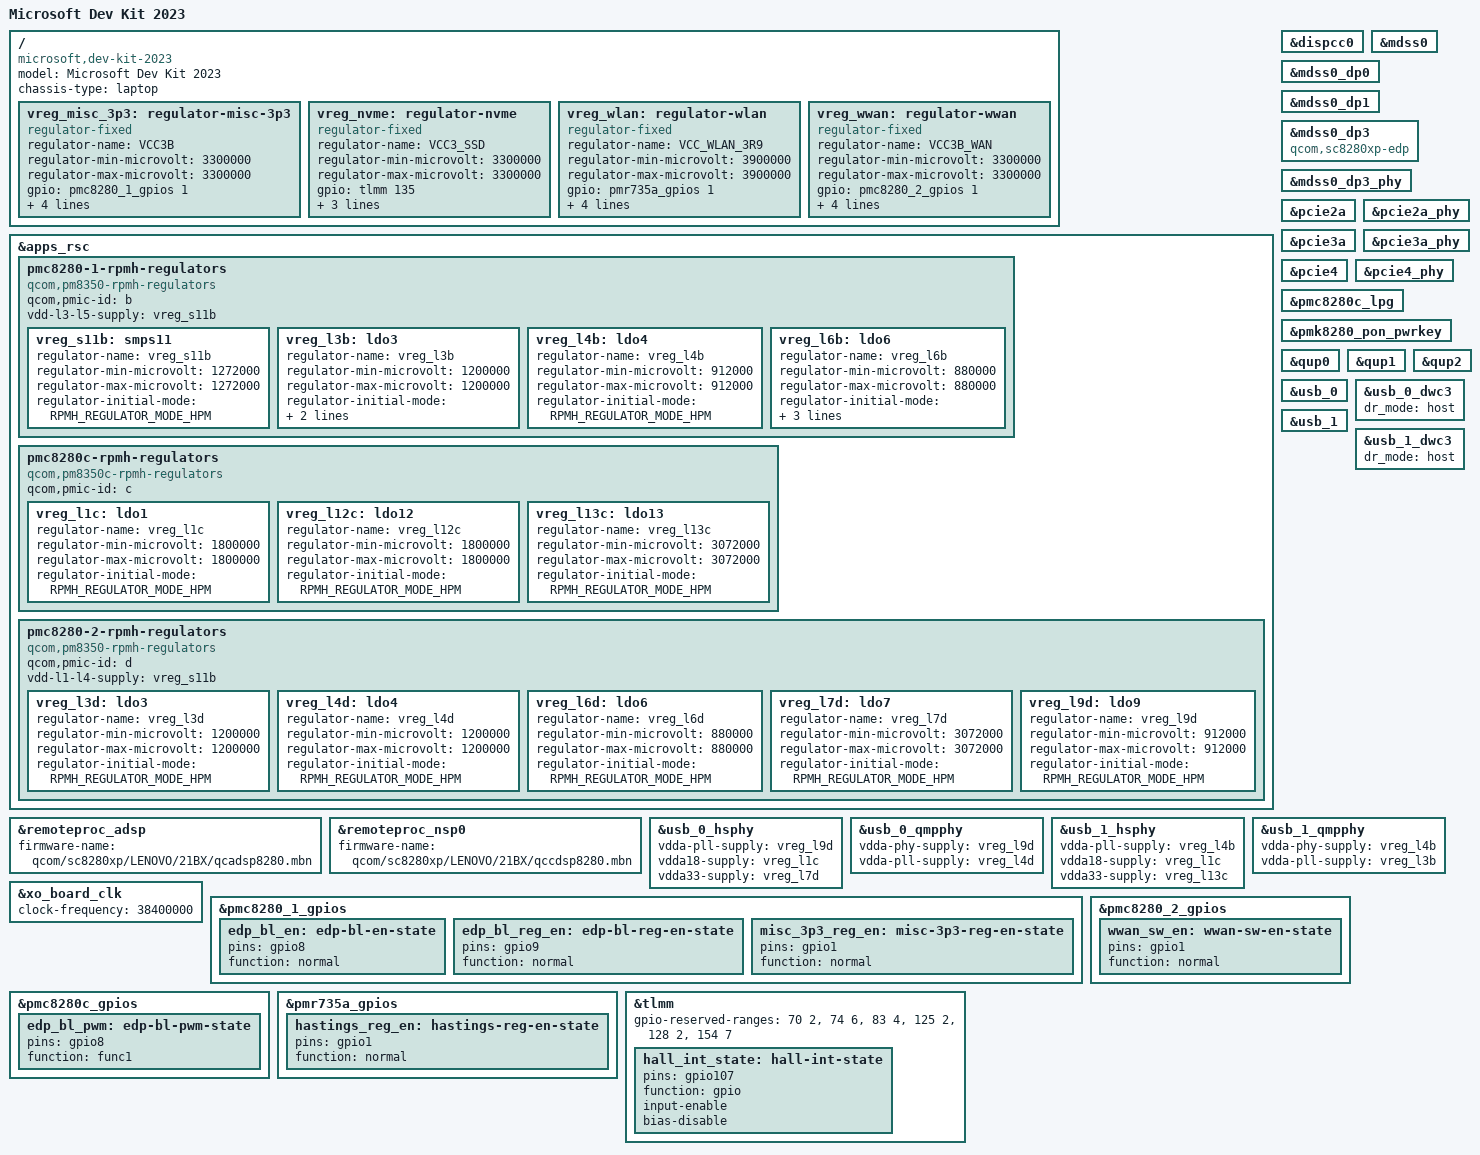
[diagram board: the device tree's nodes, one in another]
// SPDX-License-Identifier: BSD-3-Clause
/*
 * Copyright (c) 2021, The Linux Foundation. All rights reserved.
 * Copyright (c) 2022, Linaro Limited
 */

/dts-v1/;

#include <dt-bindings/gpio/gpio.h>
#include <dt-bindings/input/gpio-keys.h>
#include <dt-bindings/input/input.h>
#include <dt-bindings/regulator/qcom,rpmh-regulator.h>

#include "sc8280xp.dtsi"
#include "sc8280xp-pmics.dtsi"

/ {
	model = "Microsoft Dev Kit 2023";
	compatible = "microsoft,dev-kit-2023", "qcom,sc8280xp";
	chassis-type = "laptop";

	vreg_misc_3p3: regulator-misc-3p3 {
		compatible = "regulator-fixed";

		regulator-name = "VCC3B";
		regulator-min-microvolt = <3300000>;
		regulator-max-microvolt = <3300000>;

		gpio = <&pmc8280_1_gpios 1 GPIO_ACTIVE_HIGH>;
		enable-active-high;

		pinctrl-names = "default";
		pinctrl-0 = <&misc_3p3_reg_en>;

		regulator-boot-on;
		regulator-always-on;
	};

	vreg_nvme: regulator-nvme {
		compatible = "regulator-fixed";

		regulator-name = "VCC3_SSD";
		regulator-min-microvolt = <3300000>;
		regulator-max-microvolt = <3300000>;

		gpio = <&tlmm 135 GPIO_ACTIVE_HIGH>;
		enable-active-high;

		regulator-boot-on;
		regulator-always-on;
	};

	vreg_wlan: regulator-wlan {
		compatible = "regulator-fixed";

		regulator-name = "VCC_WLAN_3R9";
		regulator-min-microvolt = <3900000>;
		regulator-max-microvolt = <3900000>;

		gpio = <&pmr735a_gpios 1 GPIO_ACTIVE_HIGH>;
		enable-active-high;

		pinctrl-names = "default";
		pinctrl-0 = <&hastings_reg_en>;

		regulator-boot-on;
		regulator-always-on;
	};

	vreg_wwan: regulator-wwan {
		compatible = "regulator-fixed";

		regulator-name = "VCC3B_WAN";
		regulator-min-microvolt = <3300000>;
		regulator-max-microvolt = <3300000>;

		gpio = <&pmc8280_2_gpios 1 GPIO_ACTIVE_HIGH>;
		enable-active-high;

		pinctrl-names = "default";
		pinctrl-0 = <&wwan_sw_en>;

		regulator-boot-on;
		regulator-always-on;
	};
};

&apps_rsc {
	pmc8280-1-rpmh-regulators {
		compatible = "qcom,pm8350-rpmh-regulators";
		qcom,pmic-id = "b";

		vdd-l3-l5-supply = <&vreg_s11b>;

		vreg_s11b: smps11 {
			regulator-name = "vreg_s11b";
			regulator-min-microvolt = <1272000>;
			regulator-max-microvolt = <1272000>;
			regulator-initial-mode = <RPMH_REGULATOR_MODE_HPM>;
		};

		vreg_l3b: ldo3 {
			regulator-name = "vreg_l3b";
			regulator-min-microvolt = <1200000>;
			regulator-max-microvolt = <1200000>;
			regulator-initial-mode = <RPMH_REGULATOR_MODE_HPM>;
			regulator-boot-on;
		};

		vreg_l4b: ldo4 {
			regulator-name = "vreg_l4b";
			regulator-min-microvolt = <912000>;
			regulator-max-microvolt = <912000>;
			regulator-initial-mode = <RPMH_REGULATOR_MODE_HPM>;
		};

		vreg_l6b: ldo6 {
			regulator-name = "vreg_l6b";
			regulator-min-microvolt = <880000>;
			regulator-max-microvolt = <880000>;
			regulator-initial-mode = <RPMH_REGULATOR_MODE_HPM>;
			regulator-boot-on;
			regulator-always-on;	// FIXME: VDD_A_EDP_0_0P9
		};
	};

	pmc8280c-rpmh-regulators {
		compatible = "qcom,pm8350c-rpmh-regulators";
		qcom,pmic-id = "c";

		vreg_l1c: ldo1 {
			regulator-name = "vreg_l1c";
			regulator-min-microvolt = <1800000>;
			regulator-max-microvolt = <1800000>;
			regulator-initial-mode = <RPMH_REGULATOR_MODE_HPM>;
		};

		vreg_l12c: ldo12 {
			regulator-name = "vreg_l12c";
			regulator-min-microvolt = <1800000>;
			regulator-max-microvolt = <1800000>;
			regulator-initial-mode = <RPMH_REGULATOR_MODE_HPM>;
		};

		vreg_l13c: ldo13 {
			regulator-name = "vreg_l13c";
			regulator-min-microvolt = <3072000>;
			regulator-max-microvolt = <3072000>;
			regulator-initial-mode = <RPMH_REGULATOR_MODE_HPM>;
		};
	};

	pmc8280-2-rpmh-regulators {
		compatible = "qcom,pm8350-rpmh-regulators";
		qcom,pmic-id = "d";

		vdd-l1-l4-supply = <&vreg_s11b>;

		vreg_l3d: ldo3 {
			regulator-name = "vreg_l3d";
			regulator-min-microvolt = <1200000>;
			regulator-max-microvolt = <1200000>;
			regulator-initial-mode = <RPMH_REGULATOR_MODE_HPM>;
		};

		vreg_l4d: ldo4 {
			regulator-name = "vreg_l4d";
			regulator-min-microvolt = <1200000>;
			regulator-max-microvolt = <1200000>;
			regulator-initial-mode = <RPMH_REGULATOR_MODE_HPM>;
		};

		vreg_l6d: ldo6 {
			regulator-name = "vreg_l6d";
			regulator-min-microvolt = <880000>;
			regulator-max-microvolt = <880000>;
			regulator-initial-mode = <RPMH_REGULATOR_MODE_HPM>;
		};

		vreg_l7d: ldo7 {
			regulator-name = "vreg_l7d";
			regulator-min-microvolt = <3072000>;
			regulator-max-microvolt = <3072000>;
			regulator-initial-mode = <RPMH_REGULATOR_MODE_HPM>;
		};

		vreg_l9d: ldo9 {
			regulator-name = "vreg_l9d";
			regulator-min-microvolt = <912000>;
			regulator-max-microvolt = <912000>;
			regulator-initial-mode = <RPMH_REGULATOR_MODE_HPM>;
		};
	};
};

&dispcc0 {
	status = "okay";
};

&mdss0 {
	status = "okay";
};

&mdss0_dp0 {
	status = "okay";
};

&mdss0_dp1 {
	status = "okay";
};

&mdss0_dp3 {
	compatible = "qcom,sc8280xp-edp";
	status = "okay";
};

&mdss0_dp3_phy {
	status = "okay";
};

&pcie2a {
	status = "okay";
};

&pcie2a_phy {
	status = "okay";
};

&pcie3a {
	status = "okay";
};

&pcie3a_phy {
	status = "okay";
};

&pcie4 {
	status = "okay";
};

&pcie4_phy {
	status = "okay";
};

&pmc8280c_lpg {
	status = "okay";
};

&pmk8280_pon_pwrkey {
	status = "okay";
};

&qup0 {
	status = "okay";
};

&qup1 {
	status = "okay";
};

&qup2 {
	status = "okay";
};

&remoteproc_adsp {
	firmware-name = "qcom/sc8280xp/LENOVO/21BX/qcadsp8280.mbn";

	status = "okay";
};

&remoteproc_nsp0 {
	firmware-name = "qcom/sc8280xp/LENOVO/21BX/qccdsp8280.mbn";

	status = "okay";
};

&usb_0 {
	status = "okay";
};

&usb_0_dwc3 {
	/* TODO: Define USB-C connector properly */
	dr_mode = "host";
};

&usb_0_hsphy {
	vdda-pll-supply = <&vreg_l9d>;
	vdda18-supply = <&vreg_l1c>;
	vdda33-supply = <&vreg_l7d>;

	status = "okay";
};

&usb_0_qmpphy {
	vdda-phy-supply = <&vreg_l9d>;
	vdda-pll-supply = <&vreg_l4d>;

	status = "okay";
};

&usb_1 {
	status = "okay";
};

&usb_1_dwc3 {
	/* TODO: Define USB-C connector properly */
	dr_mode = "host";
};

&usb_1_hsphy {
	vdda-pll-supply = <&vreg_l4b>;
	vdda18-supply = <&vreg_l1c>;
	vdda33-supply = <&vreg_l13c>;

	status = "okay";
};

&usb_1_qmpphy {
	vdda-phy-supply = <&vreg_l4b>;
	vdda-pll-supply = <&vreg_l3b>;

	status = "okay";
};

&xo_board_clk {
	clock-frequency = <38400000>;
};

/* PINCTRL */

&pmc8280_1_gpios {
	edp_bl_en: edp-bl-en-state {
		pins = "gpio8";
		function = "normal";
	};

	edp_bl_reg_en: edp-bl-reg-en-state {
		pins = "gpio9";
		function = "normal";
	};

	misc_3p3_reg_en: misc-3p3-reg-en-state {
		pins = "gpio1";
		function = "normal";
	};
};

&pmc8280_2_gpios {
	wwan_sw_en: wwan-sw-en-state {
		pins = "gpio1";
		function = "normal";
	};
};

&pmc8280c_gpios {
	edp_bl_pwm: edp-bl-pwm-state {
		pins = "gpio8";
		function = "func1";
	};
};

&pmr735a_gpios {
	hastings_reg_en: hastings-reg-en-state {
		pins = "gpio1";
		function = "normal";
	};
};

&tlmm {
	gpio-reserved-ranges = <70 2>, <74 6>, <83 4>, <125 2>, <128 2>, <154 7>;

	hall_int_state: hall-int-state {
		pins = "gpio107";
		function = "gpio";

		input-enable;
		bias-disable;
	};
};
